# STM32G0B1 register map
File version: 1.8
CPU: CM0 r0p1, little endian, MPU, no FPU, 4 interrupt priority bits
Registers are 32-bit, read-write, reset 0x0 unless marked. A register's access mark holds for its fields unless they carry their own. Offsets are from the block's base; [hi:lo] are bit positions; {n}, {i} and the like mark numbered series.

## EXTI — External interrupt/event controller
Base 0x40021800
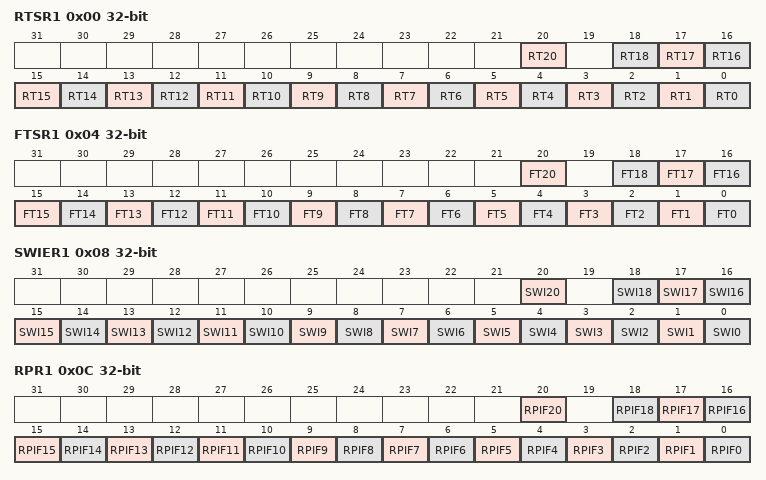
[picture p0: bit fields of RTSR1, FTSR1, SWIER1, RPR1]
0x00 RTSR1 — EXTI rising trigger selection register
  [20] RT20 — Rising trigger event configuration bit of Configurable Event line
  [n] RT{n} (n=0..18) — Rising trigger event configuration bit of Configurable Event line
0x04 FTSR1 — EXTI falling trigger selection register
  [20] FT20 — Rising trigger event configuration bit of Configurable Event input
  [n] FT{n} (n=0..18) — Falling trigger event configuration bit of configurable line
0x08 SWIER1 — EXTI software interrupt event register
  [20] SWI20 — Software rising edge event trigger on line
  [n] SWI{n} (n=0..18) — Software rising edge event trigger on line
0x0C RPR1 — EXTI rising edge pending register
  [20] RPIF20 — Rising edge event pending for configurable line
  [n] RPIF{n} (n=6..18) — Rising edge event pending for configurable line
  [5] RPIF5 — configurable event inputs x rising edge Pending bit
  [n] RPIF{n} (n=0..4) — Rising edge event pending for configurable line
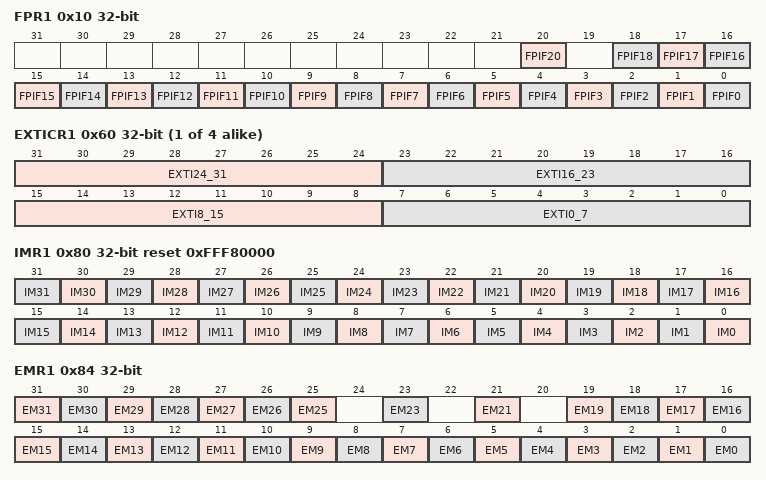
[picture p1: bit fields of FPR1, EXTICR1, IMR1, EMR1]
0x10 FPR1 — EXTI falling edge pending register
  [20] FPIF20 — Falling edge event pending for configurable line
  [n] FPIF{n} (n=0..18) — Falling edge event pending for configurable line
0x28 RTSR2 — EXTI rising trigger selection register 2
  [2] RT2 — Rising trigger event configuration bit of configurable line 34
0x2C FTSR2 — EXTI falling trigger selection register 2
  [2] FT2 — Falling trigger event configuration bit of configurable line 34
0x30 SWIER2 — EXTI software interrupt event register 2
  [2] SWI2 — Software rising edge event trigger on line 34
0x34 RPR2 — EXTI rising edge pending register 2
  [2] RPIF2 — Rising edge event pending for configurable line 34
0x38 FPR2 — EXTI falling edge pending register 2
  [2] FPIF2 — Falling edge event pending for configurable line 34
{0x5C+4i} EXTICR{i} (i=1..4) — EXTI external interrupt selection register
  [31:24] EXTI24_31 — GPIO port selection
  [23:16] EXTI16_23 — GPIO port selection
  [15:8] EXTI8_15 — GPIO port selection
  [7:0] EXTI0_7 — GPIO port selection
0x80 IMR1 reset 0xFFF80000 — EXTI CPU wakeup with interrupt mask register
  [n] IM{n} (n=0..31) — CPU wakeup with interrupt mask on event input
0x84 EMR1 (alternate view of IMR1) — EXTI CPU wakeup with event mask register
  [n] EM{n} (n=25..31) — CPU wakeup with event mask on event input
  [23] EM23 — CPU wakeup with event mask on event input
  [21] EM21 — CPU wakeup with event mask on event input
  [n] EM{n} (n=0..19) — CPU wakeup with event mask on event input
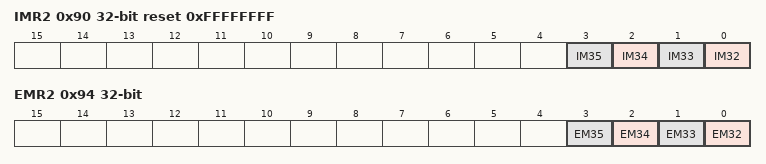
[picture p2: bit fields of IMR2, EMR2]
0x90 IMR2 reset 0xFFFFFFFF — EXTI CPU wakeup with interrupt mask register
  [n-32] IM{n} (n=32..35) — CPU wakeup with interrupt mask on event input
0x94 EMR2 — EXTI CPU wakeup with event mask register
  [n-32] EM{n} (n=32..35) — CPU wakeup with event mask on event input

## GPIOA — General-purpose I/Os
Base 0x50000000
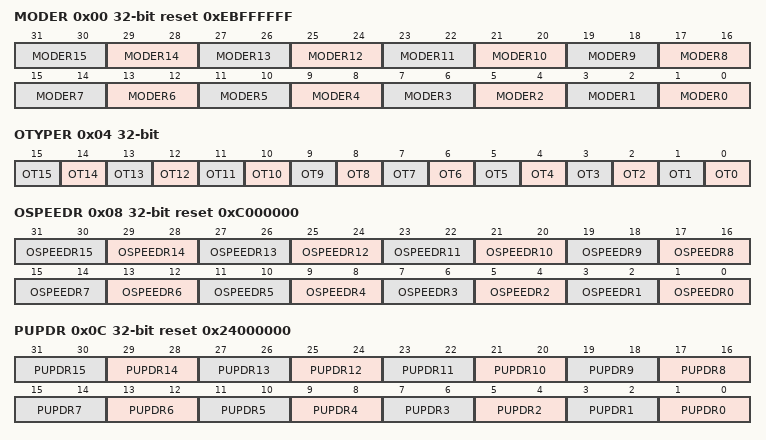
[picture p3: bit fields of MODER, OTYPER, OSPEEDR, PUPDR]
0x00 MODER reset 0xEBFFFFFF — GPIO port mode register
  [2n+1:2n] MODER{n} (n=0..15) — Port x configuration bits (y = 0..15)
0x04 OTYPER — GPIO port output type register
  [n] OT{n} (n=0..15) — Port x configuration bits (y = 0..15)
0x08 OSPEEDR reset 0xC000000 — GPIO port output speed register
  [2n+1:2n] OSPEEDR{n} (n=0..15) — Port x configuration bits (y = 0..15)
0x0C PUPDR reset 0x24000000 — GPIO port pull-up/pull-down register
  [2n+1:2n] PUPDR{n} (n=0..15) — Port x configuration bits (y = 0..15)
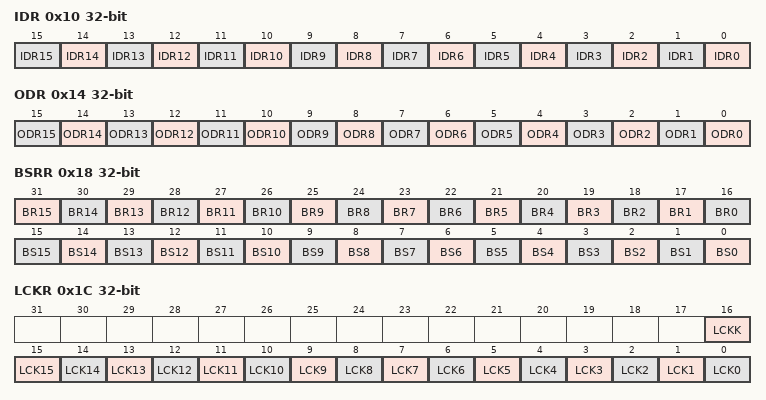
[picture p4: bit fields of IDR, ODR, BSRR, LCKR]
0x10 IDR ro — GPIO port input data register
  [n] IDR{n} (n=0..15) — Port input data (y = 0..15)
0x14 ODR — GPIO port output data register
  [n] ODR{n} (n=0..15) — Port output data (y = 0..15)
0x18 BSRR wo — GPIO port bit set/reset register
  [n+16] BR{n} (n=1..15) — Port x reset bit y (y = 0..15)
  [16] BR0 — Port x set bit y (y= 0..15)
  [n] BS{n} (n=0..15) — Port x set bit y (y= 0..15)
0x1C LCKR — GPIO port configuration lock register
  [16] LCKK — Port x lock bit y (y= 0..15)
  [n] LCK{n} (n=0..15) — Port x lock bit y (y= 0..15)
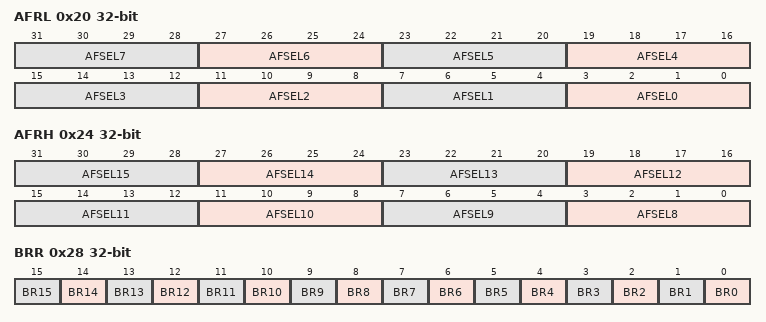
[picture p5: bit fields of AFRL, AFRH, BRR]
0x20 AFRL — GPIO alternate function low register
  [4n+3:4n] AFSEL{n} (n=0..7) — Alternate function selection for port x bit y (y = 0..7)
0x24 AFRH — GPIO alternate function high register
  [4n-29:4n-32] AFSEL{n} (n=8..15) — Alternate function selection for port x bit y (y = 8..15)
0x28 BRR wo — port bit reset register
  [n] BR{n} (n=0..15) — Port Reset bit

## GPIOB — General-purpose I/Os
Base 0x50000400
Same registers: GPIOC 0x50000800, GPIOD 0x50000C00, GPIOE 0x50001000, GPIOF 0x50001400
Registers as GPIOA; these are added or differ:
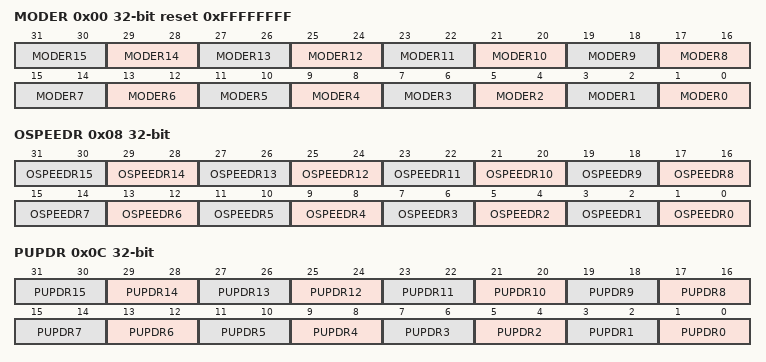
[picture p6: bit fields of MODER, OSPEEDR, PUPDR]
0x00 MODER reset 0xFFFFFFFF — GPIO port mode register
  [2n+1:2n] MODER{n} (n=0..15) — Port x configuration bits (y = 0..15)
0x08 OSPEEDR — GPIO port output speed register
  [2n+1:2n] OSPEEDR{n} (n=0..15) — Port x configuration bits (y = 0..15)
0x0C PUPDR — GPIO port pull-up/pull-down register
  [2n+1:2n] PUPDR{n} (n=0..15) — Port x configuration bits (y = 0..15)
